# iom480ae register map
Registers from a debugger description file.
Registers are 32-bit, access not given, no defined reset value unless marked. A register's access mark holds for its fields unless they carry their own. Addresses are absolute; registers are grouped by the start of their names; lines under a group give offsets from that group; [hi:lo] are bit positions; {n}, {i} and the like mark numbered series; 'fields as' and 'values as' point back to an identical list; <NAME> marks a mode.

## SYS
0x40000000 SYS_SYS_PDID
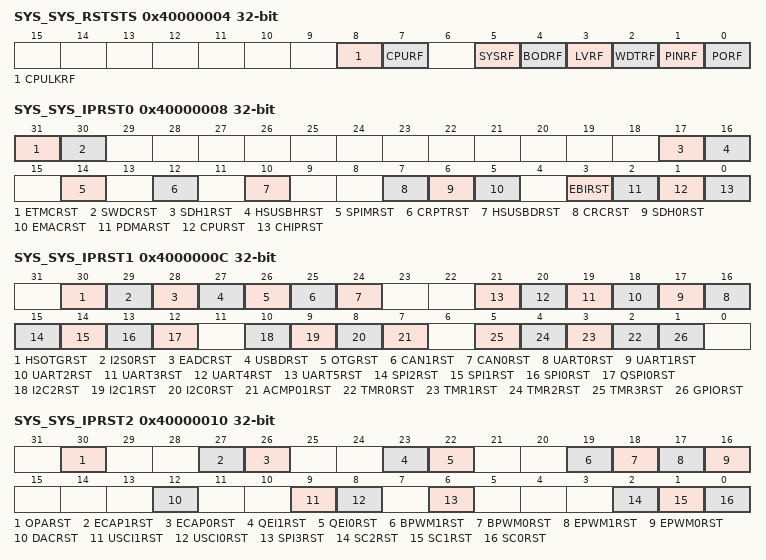
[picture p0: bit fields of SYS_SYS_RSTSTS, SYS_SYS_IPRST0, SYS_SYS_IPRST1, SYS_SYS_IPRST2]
0x40000004 SYS_SYS_RSTSTS
  [8] CPULKRF, [7] CPURF, [5] SYSRF, [4] BODRF, [3] LVRF, [2] WDTRF, [1] PINRF, [0] PORF
0x40000008 SYS_SYS_IPRST0
  [31] ETMCRST, [30] SWDCRST, [17] SDH1RST, [16] HSUSBHRST, [14] SPIMRST, [12] CRPTRST, [10] HSUSBDRST, [7] CRCRST, [6] SDH0RST, [5] EMACRST, [3] EBIRST, [2] PDMARST, [1] CPURST, [0] CHIPRST
0x4000000C SYS_SYS_IPRST1
  [30] HSOTGRST, [29] I2S0RST, [28] EADCRST, [27] USBDRST, [26] OTGRST, [25] CAN1RST, [24] CAN0RST, [n+16] UART{n}RST (n=0..5), [15] SPI2RST, [14] SPI1RST, [13] SPI0RST, [12] QSPI0RST, [10] I2C2RST, [9] I2C1RST, [8] I2C0RST, [7] ACMP01RST, [n+2] TMR{n}RST (n=0..3), [1] GPIORST
0x40000010 SYS_SYS_IPRST2
  [30] OPARST, [27] ECAP1RST, [26] ECAP0RST, [23] QEI1RST, [22] QEI0RST, [19] BPWM1RST, [18] BPWM0RST, [17] EPWM1RST, [16] EPWM0RST, [12] DACRST, [9] USCI1RST, [8] USCI0RST, [6] SPI3RST, [2] SC2RST, [1] SC1RST, [0] SC0RST
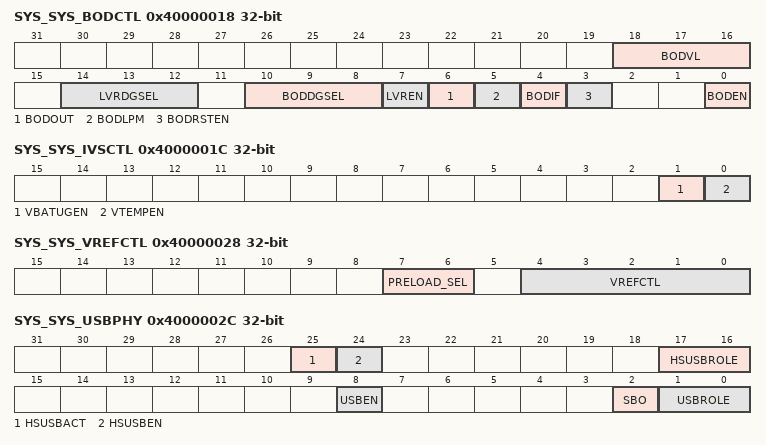
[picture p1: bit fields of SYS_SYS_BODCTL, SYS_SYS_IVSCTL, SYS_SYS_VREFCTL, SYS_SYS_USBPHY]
0x40000018 SYS_SYS_BODCTL
  [18:16] BODVL, [14:12] LVRDGSEL, [10:8] BODDGSEL, [7] LVREN, [6] BODOUT, [5] BODLPM, [4] BODIF, [3] BODRSTEN, [0] BODEN
0x4000001C SYS_SYS_IVSCTL
  [1] VBATUGEN, [0] VTEMPEN
0x40000024 SYS_SYS_PORCTL
  [15:0] POROFF
0x40000028 SYS_SYS_VREFCTL
  [7:6] PRELOAD_SEL, [4:0] VREFCTL
0x4000002C SYS_SYS_USBPHY
  [25] HSUSBACT, [24] HSUSBEN, [17:16] HSUSBROLE, [8] USBEN, [2] SBO, [1:0] USBROLE
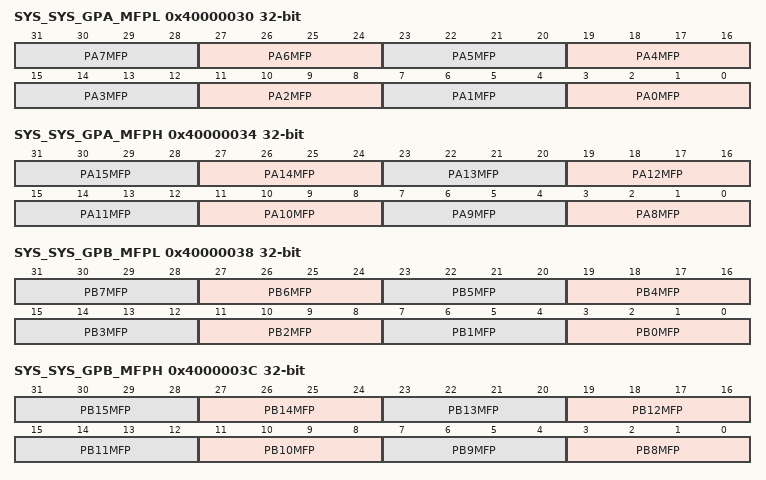
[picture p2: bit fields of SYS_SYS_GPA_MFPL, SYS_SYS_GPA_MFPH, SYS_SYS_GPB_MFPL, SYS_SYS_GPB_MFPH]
0x40000030 SYS_SYS_GPA_MFPL
  [4n+3:4n] PA{n}MFP (n=0..7)
0x40000034 SYS_SYS_GPA_MFPH
  [4n-29:4n-32] PA{n}MFP (n=8..15)
0x40000038 SYS_SYS_GPB_MFPL
  [4n+3:4n] PB{n}MFP (n=0..7)
0x4000003C SYS_SYS_GPB_MFPH
  [4n-29:4n-32] PB{n}MFP (n=8..15)
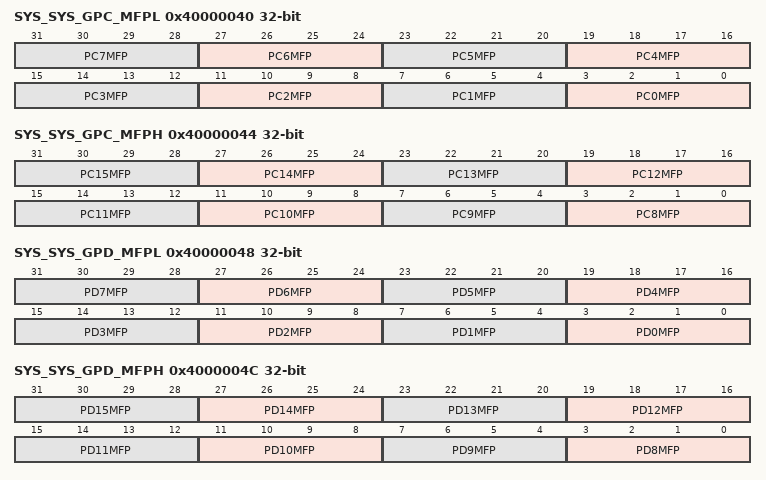
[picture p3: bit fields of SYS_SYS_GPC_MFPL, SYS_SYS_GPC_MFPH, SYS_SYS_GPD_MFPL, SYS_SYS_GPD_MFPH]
0x40000040 SYS_SYS_GPC_MFPL
  [4n+3:4n] PC{n}MFP (n=0..7)
0x40000044 SYS_SYS_GPC_MFPH
  [4n-29:4n-32] PC{n}MFP (n=8..15)
0x40000048 SYS_SYS_GPD_MFPL
  [4n+3:4n] PD{n}MFP (n=0..7)
0x4000004C SYS_SYS_GPD_MFPH
  [4n-29:4n-32] PD{n}MFP (n=8..15)
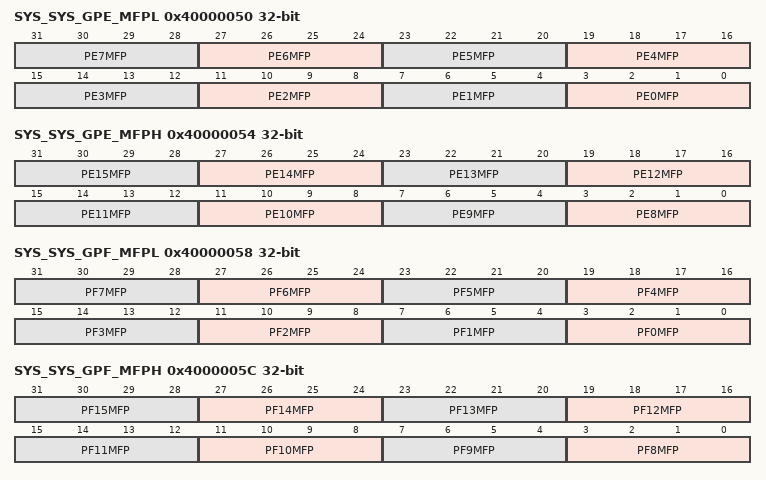
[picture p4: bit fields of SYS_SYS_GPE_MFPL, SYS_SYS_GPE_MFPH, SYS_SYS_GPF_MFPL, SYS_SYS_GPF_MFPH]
0x40000050 SYS_SYS_GPE_MFPL
  [4n+3:4n] PE{n}MFP (n=0..7)
0x40000054 SYS_SYS_GPE_MFPH
  [4n-29:4n-32] PE{n}MFP (n=8..15)
0x40000058 SYS_SYS_GPF_MFPL
  [4n+3:4n] PF{n}MFP (n=0..7)
0x4000005C SYS_SYS_GPF_MFPH
  [4n-29:4n-32] PF{n}MFP (n=8..15)
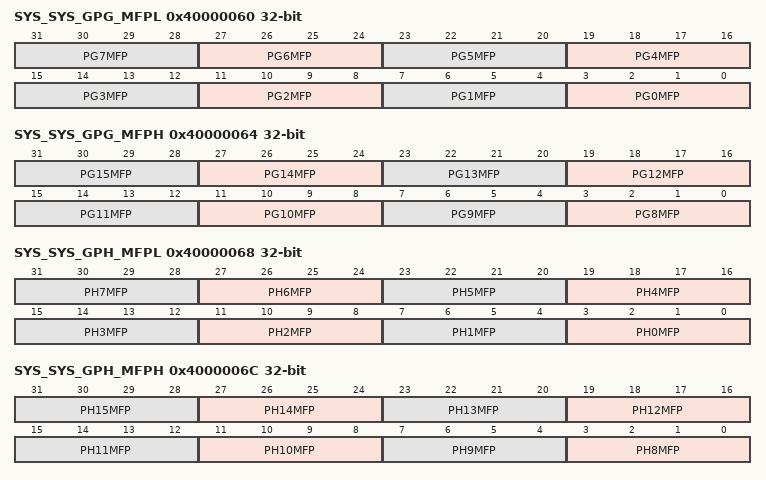
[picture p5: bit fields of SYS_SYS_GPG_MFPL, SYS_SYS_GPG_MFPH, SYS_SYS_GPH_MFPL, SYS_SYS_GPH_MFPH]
0x40000060 SYS_SYS_GPG_MFPL
  [4n+3:4n] PG{n}MFP (n=0..7)
0x40000064 SYS_SYS_GPG_MFPH
  [4n-29:4n-32] PG{n}MFP (n=8..15)
0x40000068 SYS_SYS_GPH_MFPL
  [4n+3:4n] PH{n}MFP (n=0..7)
0x4000006C SYS_SYS_GPH_MFPH
  [4n-29:4n-32] PH{n}MFP (n=8..15)
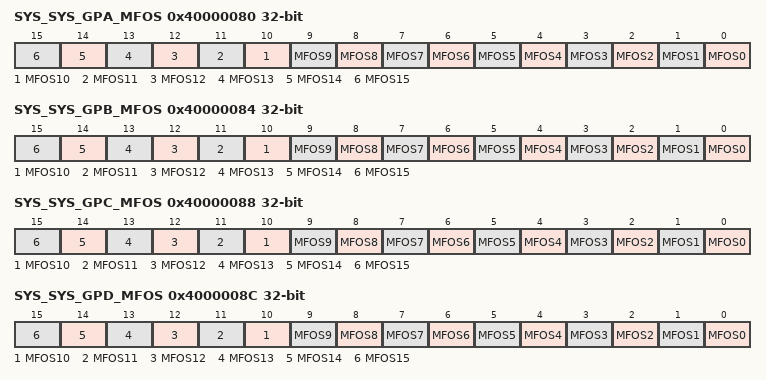
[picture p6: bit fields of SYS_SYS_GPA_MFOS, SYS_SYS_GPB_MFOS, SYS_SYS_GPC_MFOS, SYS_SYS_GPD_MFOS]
0x40000080 SYS_SYS_GPA_MFOS
  [n] MFOS{n} (n=0..15)
0x40000084 SYS_SYS_GPB_MFOS
  [n] MFOS{n} (n=0..15)
0x40000088 SYS_SYS_GPC_MFOS
  [n] MFOS{n} (n=0..15)
0x4000008C SYS_SYS_GPD_MFOS
  [n] MFOS{n} (n=0..15)
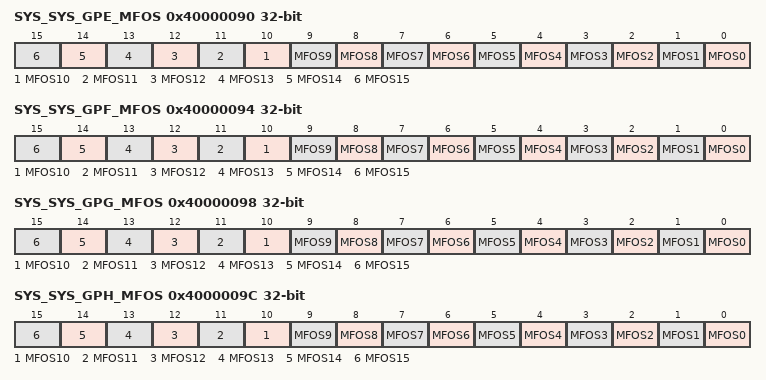
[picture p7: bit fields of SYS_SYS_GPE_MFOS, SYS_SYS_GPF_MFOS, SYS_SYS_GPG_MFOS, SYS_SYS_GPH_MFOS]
0x40000090 SYS_SYS_GPE_MFOS
  [n] MFOS{n} (n=0..15)
0x40000094 SYS_SYS_GPF_MFOS
  [n] MFOS{n} (n=0..15)
0x40000098 SYS_SYS_GPG_MFOS
  [n] MFOS{n} (n=0..15)
0x4000009C SYS_SYS_GPH_MFOS
  [n] MFOS{n} (n=0..15)
0x400000C0 SYS_SYS_SRAM_INTCTL
  [0] PERRIEN
0x400000C4 SYS_SYS_SRAM_STATUS
  [0] PERRIF
0x400000C8 SYS_SYS_SRAM_ERRADDR
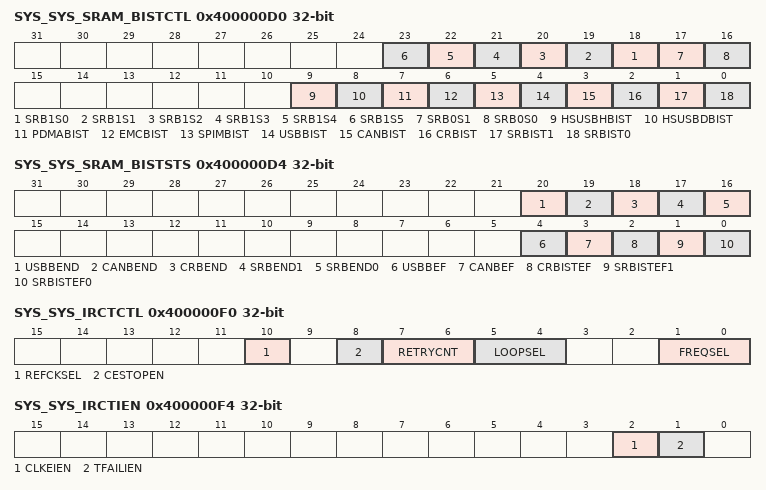
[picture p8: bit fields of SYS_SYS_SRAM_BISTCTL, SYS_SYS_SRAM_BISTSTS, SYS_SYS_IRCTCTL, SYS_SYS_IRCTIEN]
0x400000D0 SYS_SYS_SRAM_BISTCTL
  [n+18] SRB1S{n} (n=0..5), [17] SRB0S1, [16] SRB0S0, [9] HSUSBHBIST, [8] HSUSBDBIST, [7] PDMABIST, [6] EMCBIST, [5] SPIMBIST, [4] USBBIST, [3] CANBIST, [2] CRBIST, [1] SRBIST1, [0] SRBIST0
0x400000D4 SYS_SYS_SRAM_BISTSTS
  [20] USBBEND, [19] CANBEND, [18] CRBEND, [17] SRBEND1, [16] SRBEND0, [4] USBBEF, [3] CANBEF, [2] CRBISTEF, [1] SRBISTEF1, [0] SRBISTEF0
0x400000F0 SYS_SYS_IRCTCTL
  [10] REFCKSEL, [8] CESTOPEN, [7:6] RETRYCNT, [5:4] LOOPSEL, [1:0] FREQSEL
0x400000F4 SYS_SYS_IRCTIEN
  [2] CLKEIEN, [1] TFAILIEN
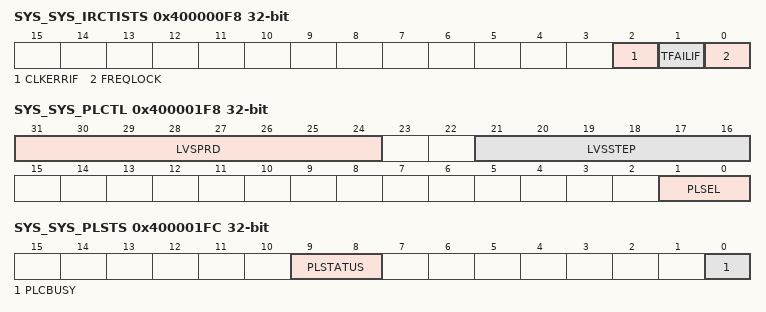
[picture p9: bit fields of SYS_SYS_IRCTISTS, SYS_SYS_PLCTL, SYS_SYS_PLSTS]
0x400000F8 SYS_SYS_IRCTISTS
  [2] CLKERRIF, [1] TFAILIF, [0] FREQLOCK
0x40000100 SYS_SYS_REGLCTL
  [7:0] REGLCTL
0x400001F8 SYS_SYS_PLCTL
  [31:24] LVSPRD, [21:16] LVSSTEP, [1:0] PLSEL
0x400001FC SYS_SYS_PLSTS
  [9:8] PLSTATUS, [0] PLCBUSY
0x40000400 SYS_SYS_AHBMCTL
  [0] INTACTEN
